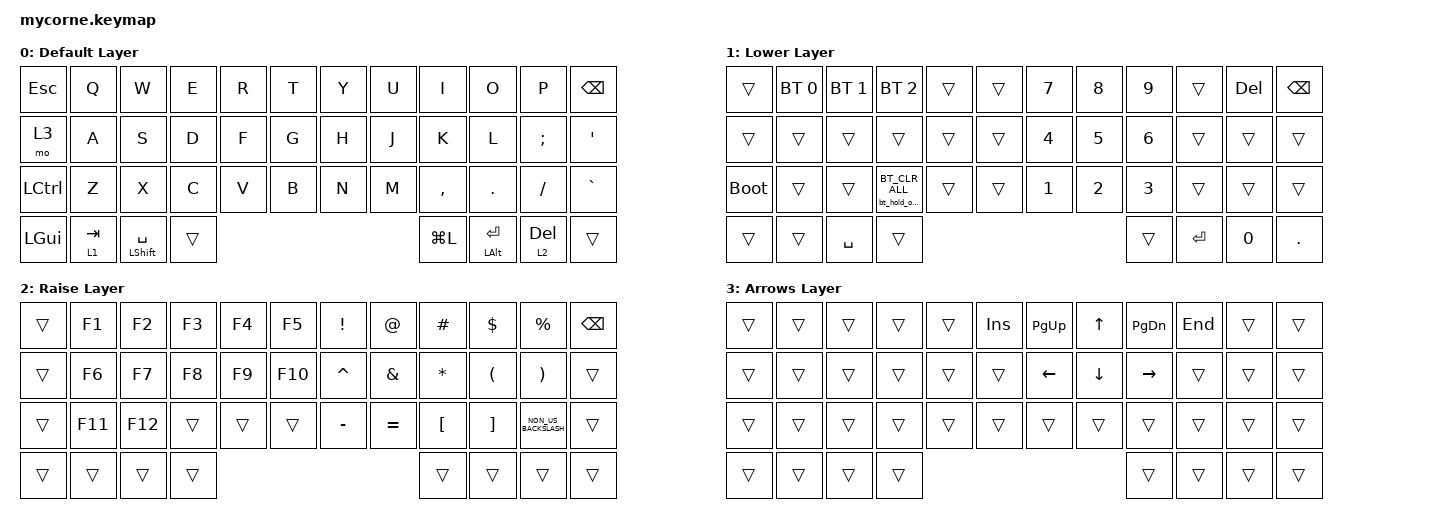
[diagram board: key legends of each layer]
#include <behaviors.dtsi>
#include <dt-bindings/zmk/bt.h>
#include <dt-bindings/zmk/keys.h>

/ {
    behaviors {
        hold_mo_tap_kp: hold_mo_tap_kp {
            compatible = "zmk,behavior-hold-tap";
            label = "HOLD_MO_TAP_KP";
            #binding-cells = <2>;
            tapping-term-ms = <350>;
            flavor = "tap-preferred";
            bindings = <&mo>, <&kp>;
        };

        hold_kp_tap_kp: hold_kp_tap_kp {
            compatible = "zmk,behavior-hold-tap";
            label = "HOLD_KP_TAP_KP";
            bindings = <&kp>, <&kp>;

            #binding-cells = <2>;
            tapping-term-ms = <300>;
            flavor = "tap-preferred";
        };

        bt_hold_only: bt_hold_only {
            compatible = "zmk,behavior-hold-tap";
            label = "BT_HOLD_ONLY";
            bindings = <&bt>, <&trans>;

            #binding-cells = <2>;
            tapping-term-ms = <2000>;
            flavor = "tap-preferred";
        };

        kp_long_hold: kp_long_hold {
            compatible = "zmk,behavior-hold-tap";
            label = "KP_LONG_HOLD";
            bindings = <&kp>, <&trans>;

            #binding-cells = <2>;
            tapping-term-ms = <2000>;
        };
    };

    keymap {
        compatible = "zmk,keymap";

        default_layer {
            display-name = "Default Layer";
            bindings = <
&kp ESCAPE        &kp Q                  &kp W                             &kp E   &kp R  &kp T    &kp Y  &kp U  &kp I      &kp O                           &kp P                     &kp BSPC
&mo 3             &kp A                  &kp S                             &kp D   &kp F  &kp G    &kp H  &kp J  &kp K      &kp L                           &kp SEMI                  &kp SQT
&kp LEFT_CONTROL  &kp Z                  &kp X                             &kp C   &kp V  &kp B    &kp N  &kp M  &kp COMMA  &kp DOT                         &kp FSLH                  &kp GRAVE
&kp LGUI          &hold_mo_tap_kp 1 TAB  &hold_kp_tap_kp LEFT_SHIFT SPACE  &trans                                &kp LG(L)  &hold_kp_tap_kp LEFT_ALT ENTER  &hold_mo_tap_kp 2 DELETE  &trans
            >;

            sensor-bindings = <&inc_dec_kp C_VOL_UP C_VOL_DN>;
        };

        lower_layer {
            display-name = "Lower Layer";
            bindings = <
&trans       &bt BT_SEL 0  &bt BT_SEL 1  &bt BT_SEL 2              &trans  &trans    &kp N7  &kp N8  &kp N9  &trans     &kp DELETE  &kp BSPC
&trans       &trans        &trans        &trans                    &trans  &trans    &kp N4  &kp N5  &kp N6  &trans     &trans      &trans
&bootloader  &trans        &trans        &bt_hold_only BT_CLR_ALL  &trans  &trans    &kp N1  &kp N2  &kp N3  &trans     &trans      &trans
&trans       &trans        &kp SPACE     &trans                                                      &trans  &kp ENTER  &kp N0      &kp PERIOD
            >;

            sensor-bindings = <&inc_dec_kp C_BRI_UP C_BRI_DN>;
        };

        raise_layer {
            display-name = "Raise Layer";
            bindings = <
&trans  &kp F1   &kp F2   &kp F3  &kp F4  &kp F5     &kp EXCLAMATION  &kp AT_SIGN    &kp HASH          &kp DOLLAR            &kp PERCENT            &kp BSPC
&trans  &kp F6   &kp F7   &kp F8  &kp F9  &kp F10    &kp CARET        &kp AMPERSAND  &kp ASTERISK      &kp LEFT_PARENTHESIS  &kp RIGHT_PARENTHESIS  &trans
&trans  &kp F11  &kp F12  &trans  &trans  &trans     &kp MINUS        &kp EQUAL      &kp LEFT_BRACKET  &kp RIGHT_BRACKET     &kp NON_US_BACKSLASH   &trans
&trans  &trans   &trans   &trans                                                     &trans            &trans                &trans                 &trans
            >;

            sensor-bindings = <&inc_dec_kp C_VOL_UP C_VOL_DN>;
        };

        layer_3 {
            display-name = "Arrows Layer";
            bindings = <
&trans  &trans  &trans  &trans  &trans  &kp INS    &kp PAGE_UP  &kp UP    &kp PAGE_DOWN  &kp END  &trans  &trans
&trans  &trans  &trans  &trans  &trans  &trans     &kp LEFT     &kp DOWN  &kp RIGHT      &trans   &trans  &trans
&trans  &trans  &trans  &trans  &trans  &trans     &trans       &trans    &trans         &trans   &trans  &trans
&trans  &trans  &trans  &trans                                            &trans         &trans   &trans  &trans
            >;

            sensor-bindings = <&inc_dec_kp C_VOL_UP C_VOL_DN>;
        };
    };
};
